# R7FA8M1AH register map
Vendor: Renesas; Series: RA8; File version: 1.2
CPU: CM85 r0p0, little endian, MPU, FPU, VTOR, 4 interrupt priority bits
Registers are 32-bit, read-write, reset 0x0 unless marked. A register's access mark holds for its fields unless they carry their own. Offsets are from the block's base; [hi:lo] are bit positions; {n}, {i} and the like mark numbered series; 'fields as' and 'values as' point back to an identical list.

## DSILINK (part 1 of 4)
Base 0x40346000
Same registers: DSILINK_NS 0x50346000
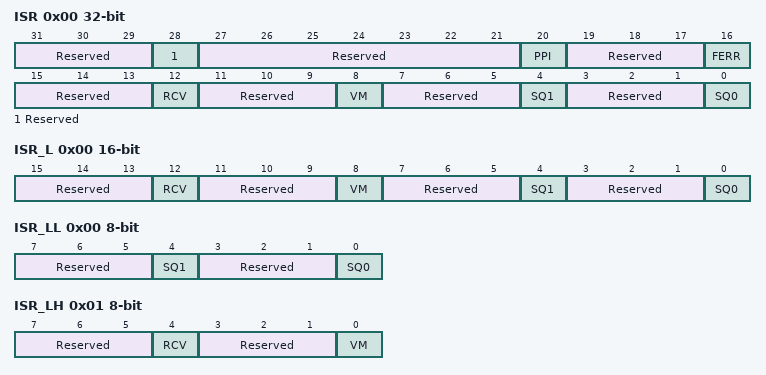
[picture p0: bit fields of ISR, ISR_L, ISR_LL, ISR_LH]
0x00 ISR ro — Interrupt Status Register
  [31:29] Reserved — These bits are read as 000.
  [28] Reserved — This bit is read as 0.
  [27:21] Reserved — These bits are read as 0000000.
  [20] PPI — PPI Interrupt Flag
    0=No interrupt detected; 1=PPI interrupt detected
  [19:17] Reserved — These bits are read as 000.
  [16] FERR — Fatal Error Interrupt Flag
    0=No interrupt detected; 1=Fatal Error interrupt detected
  [15:13] Reserved — These bits are read as 000.
  [12] RCV — Receive Interrupt Flag
    0=No interrupt detected; 1=Receive interrupt detected
  [11:9] Reserved — These bits are read as 000.
  [8] VM — Video Mode Interrupt Flag
    0=No interrupt detected; 1=Video Mode interrupt detected
  [7:5] Reserved — These bits are read as 000.
  [4] SQ1 — Sequence Channel-1 Interrupt Flag
    0=No interrupt detected; 1=Sequence Operation Channel-1 interrupt detected
  [3:1] Reserved — These bits are read as 000.
  [0] SQ0 — Sequence Channel-0 Interrupt Flag
    0=No interrupt detected; 1=Sequence Operation Channel-0 interrupt detected
0x00 ISR_L 16-bit ro (alternate view of ISR) — Interrupt Status Register
  [15:13] Reserved — These bits are read as 000.
  [12] RCV — Receive Interrupt Flag
    0=No interrupt detected; 1=Receive interrupt detected
  [11:9] Reserved — These bits are read as 000.
  [8] VM — Video Mode Interrupt Flag
    0=No interrupt detected; 1=Video Mode interrupt detected
  [7:5] Reserved — These bits are read as 000.
  [4] SQ1 — Sequence Channel-1 Interrupt Flag
    values as ISR.SQ1
  [3:1] Reserved — These bits are read as 000.
  [0] SQ0 — Sequence Channel-0 Interrupt Flag
    values as ISR.SQ0
0x00 ISR_LL 8-bit ro (alternate view of ISR) — Interrupt Status Register
  [7:5] Reserved — These bits are read as 000.
  [4] SQ1 — Sequence Channel-1 Interrupt Flag
    values as ISR.SQ1
  [3:1] Reserved — These bits are read as 000.
  [0] SQ0 — Sequence Channel-0 Interrupt Flag
    values as ISR.SQ0
0x01 ISR_LH 8-bit ro (alternate view of ISR) — Interrupt Status Register
  [7:5] Reserved — These bits are read as 000.
  [4] RCV — Receive Interrupt Flag
    0=No interrupt detected; 1=Receive interrupt detected
  [3:1] Reserved — These bits are read as 000.
  [0] VM — Video Mode Interrupt Flag
    0=No interrupt detected; 1=Video Mode interrupt detected
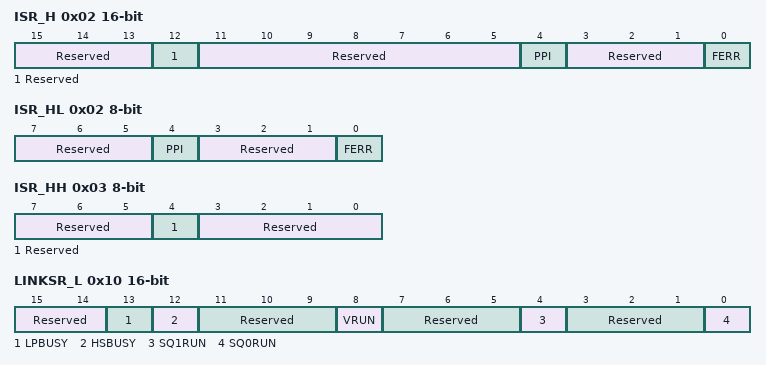
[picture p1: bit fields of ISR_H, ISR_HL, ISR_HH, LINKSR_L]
0x02 ISR_H 16-bit ro (alternate view of ISR) — Interrupt Status Register
  [15:13] Reserved — These bits are read as 000.
  [12] Reserved — This bit is read as 0.
  [11:5] Reserved — These bits are read as 0000000.
  [4] PPI — PPI Interrupt Flag
    0=No interrupt detected; 1=PPI interrupt detected
  [3:1] Reserved — These bits are read as 000.
  [0] FERR — Fatal Error Interrupt Flag
    0=No interrupt detected; 1=Fatal Error interrupt detected
0x02 ISR_HL 8-bit ro (alternate view of ISR) — Interrupt Status Register
  [7:5] Reserved — These bits are read as 000.
  [4] PPI — PPI Interrupt Flag
    0=No interrupt detected; 1=PPI interrupt detected
  [3:1] Reserved — These bits are read as 000.
  [0] FERR — Fatal Error Interrupt Flag
    0=No interrupt detected; 1=Fatal Error interrupt detected
0x03 ISR_HH 8-bit ro (alternate view of ISR) — Interrupt Status Register
  [7:5] Reserved — These bits are read as 000.
  [4] Reserved — This bit is read as 0.
  [3:0] Reserved — These bits are read as 0000.
0x10 LINKSR_L 16-bit ro (alternate view of LINKSR) — Link Status Register
  [15:14] Reserved — These bits are read as 00.
  [13] LPBUSY — LP Operation Busy Flag
    0=LP mode stopped; 1=LP mode in operation
  [12] HSBUSY — HS Operation Busy Flag
    0=HS mode stopped; 1=HS mode in operation
  [11:9] Reserved — These bits are read as 000.
  [8] VRUN — Video Mode Operation Running Flag
    0=Video mode stopped; 1=Video mode in operation
  [7:5] Reserved — These bits are read as 000.
  [4] SQ1RUN — Sequence Channel-1 Running Flag
    0=Sequence Operation Channel-1 stopped; 1=Sequence Operation Channel-1 in operation
  [3:1] Reserved — These bits are read as 000.
  [0] SQ0RUN — Sequence Channel-0 Running Flag
    0=Sequence Operation Channel-0 stopped; 1=Sequence Operation Channel-0 in operation
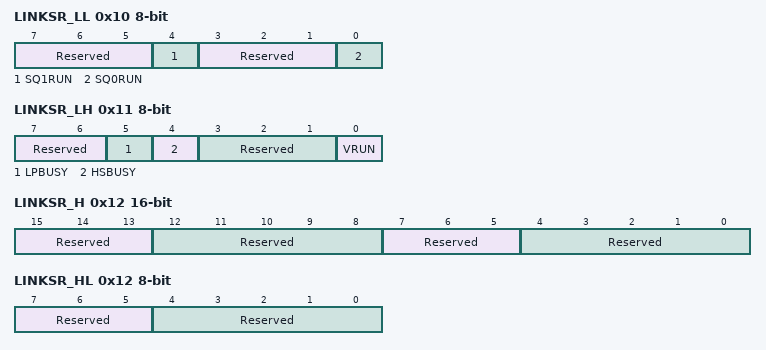
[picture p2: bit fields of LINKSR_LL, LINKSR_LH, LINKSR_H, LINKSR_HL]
0x10 LINKSR_LL 8-bit ro (alternate view of LINKSR) — Link Status Register
  [7:5] Reserved — These bits are read as 000.
  [4] SQ1RUN — Sequence Channel-1 Running Flag
    values as LINKSR_L.SQ1RUN
  [3:1] Reserved — These bits are read as 000.
  [0] SQ0RUN — Sequence Channel-0 Running Flag
    values as LINKSR_L.SQ0RUN
0x11 LINKSR_LH 8-bit ro (alternate view of LINKSR) — Link Status Register
  [7:6] Reserved — These bits are read as 00.
  [5] LPBUSY — LP Operation Busy Flag
    0=LP mode stopped; 1=LP mode in operation
  [4] HSBUSY — HS Operation Busy Flag
    0=HS mode stopped; 1=HS mode in operation
  [3:1] Reserved — These bits are read as 000.
  [0] VRUN — Video Mode Operation Running Flag
    0=Video mode stopped; 1=Video mode in operation
0x12 LINKSR_H 16-bit ro (alternate view of LINKSR) — Link Status Register
  [15:13] Reserved — These bits are read as 000.
  [12:8] Reserved — These bits are read as 00000.
  [7:5] Reserved — These bits are read as 000.
  [4:0] Reserved — These bits are read as 00000.
0x12 LINKSR_HL 8-bit ro (alternate view of LINKSR) — Link Status Register
  [7:5] Reserved — These bits are read as 000.
  [4:0] Reserved — These bits are read as 00000.
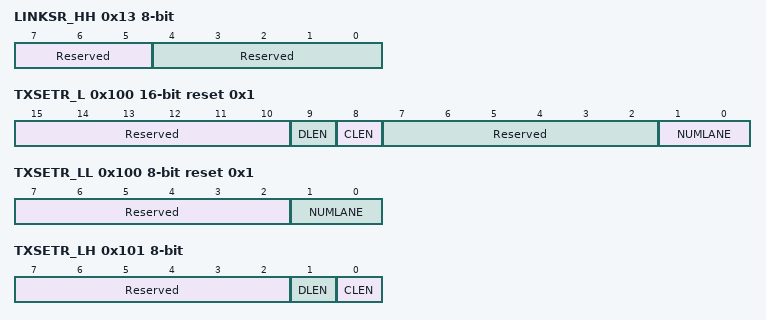
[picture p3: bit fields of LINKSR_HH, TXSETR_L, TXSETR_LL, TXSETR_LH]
0x13 LINKSR_HH 8-bit ro (alternate view of LINKSR) — Link Status Register
  fields as LINKSR_HL
0x100 TXSETR_L 16-bit reset 0x1 (alternate view of TXSETR) — Transmit Set Register
  [15:10] Reserved — These bits are read as 000000. The write value should be 000000.
  [9] DLEN — Data Lane Enable
    0=Disable; 1=Enable
  [8] CLEN — Clock Lane Enable
    0=Disable; 1=Enable
  [7:2] Reserved — These bits are read as 000000. The write value should be 000000.
  [1:0] NUMLANE — Number of Lane
    0=1 Lane (Use of Lane-0); 1=2 Lane (Use of Lane-0 and Lane-1)
0x100 TXSETR_LL 8-bit reset 0x1 (alternate view of TXSETR) — Transmit Set Register
  [7:2] Reserved — These bits are read as 000000. The write value should be 000000.
  [1:0] NUMLANE — Number of Lane
    values as TXSETR_L.NUMLANE
0x101 TXSETR_LH 8-bit (alternate view of TXSETR) — Transmit Set Register
  [7:2] Reserved — These bits are read as 000000. The write value should be 000000.
  [1] DLEN — Data Lane Enable
    0=Disable; 1=Enable
  [0] CLEN — Clock Lane Enable
    0=Disable; 1=Enable
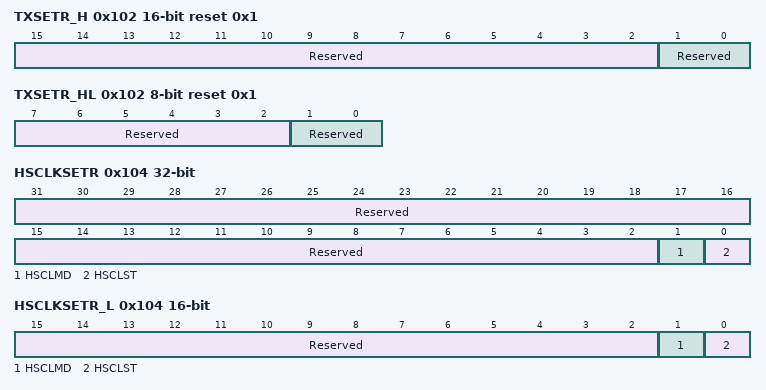
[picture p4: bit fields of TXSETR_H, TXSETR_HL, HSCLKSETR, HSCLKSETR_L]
0x102 TXSETR_H 16-bit ro reset 0x1 (alternate view of TXSETR) — Transmit Set Register
  [15:2] Reserved — These bits are read as 00000000000000.
  [1:0] Reserved — These bits are read as 01.
0x102 TXSETR_HL 8-bit ro reset 0x1 (alternate view of TXSETR) — Transmit Set Register
  [7:2] Reserved — These bits are read as 000000.
  [1:0] Reserved — These bits are read as 01.
0x104 HSCLKSETR — HS Clock Set Register
  [31:2] Reserved — These bits are read as 000000000000000000000000000000. The write value should be 000000000000000000000000000000.
  [1] HSCLMD — HS Clock Running Mode
    0=Non-continuous clock mode; 1=Continuous clock mode
  [0] HSCLST — HS Clock Start
    0=Stop HS transmission (keep LP state); 1=Start HS transmission
0x104 HSCLKSETR_L 16-bit (alternate view of HSCLKSETR) — HS Clock Set Register
  [15:2] Reserved — These bits are read as 00000000000000. The write value should be 00000000000000.
  [1] HSCLMD — HS Clock Running Mode
    0=Non-continuous clock mode; 1=Continuous clock mode
  [0] HSCLST — HS Clock Start
    values as HSCLKSETR.HSCLST
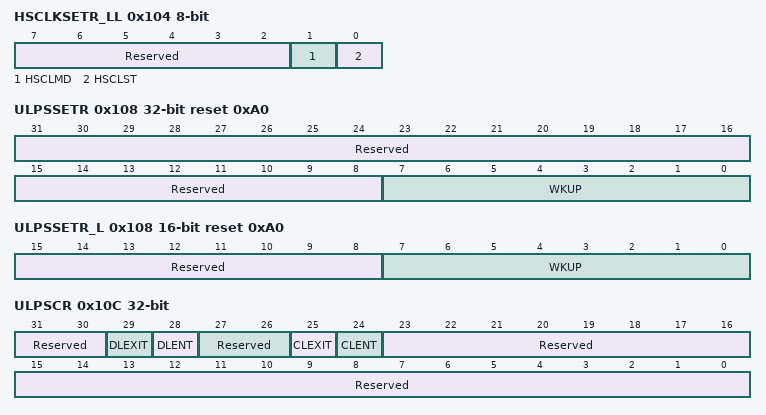
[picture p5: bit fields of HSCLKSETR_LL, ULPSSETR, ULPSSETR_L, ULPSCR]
0x104 HSCLKSETR_LL 8-bit (alternate view of HSCLKSETR) — HS Clock Set Register
  [7:2] Reserved — These bits are read as 000000. The write value should be 000000.
  [1] HSCLMD — HS Clock Running Mode
    0=Non-continuous clock mode; 1=Continuous clock mode
  [0] HSCLST — HS Clock Start
    values as HSCLKSETR.HSCLST
0x108 ULPSSETR reset 0xA0 — ULPS Set Register
  [31:8] Reserved — These bits are read as 000000000000000000000000. The write value should be 000000000000000000000000.
  [7:0] WKUP — ULPS Wakeup Period
0x108 ULPSSETR_L 16-bit reset 0xA0 (alternate view of ULPSSETR) — ULPS Set Register
  [15:8] Reserved — These bits are read as 00000000. The write value should be 00000000.
  [7:0] WKUP — ULPS Wakeup Period
0x108 ULPSSETR_LL 8-bit reset 0xA0 (alternate view of ULPSSETR) — ULPS Set Register
  [7:0] WKUP — ULPS Wakeup Period
0x10C ULPSCR wo — ULPS Control Register
  [31:30] Reserved — The write value should be 00.
  [29] DLEXIT — DL ULPS Exit
    0=No operation; 1=Data Lanes exit from ULPS
  [28] DLENT — DL ULPS Enter
    0=No operation; 1=Transition Data Lanes to ULPS
  [27:26] Reserved — The write value should be 00.
  [25] CLEXIT — CL ULPS Exit
    0=No operation; 1=Clock Lane exits from ULPS
  [24] CLENT — CL ULPS Enter
    0=No operation; 1=Transition Clock Lane to ULPS
  [23:0] Reserved — The write value should be 000000000000000000000000.
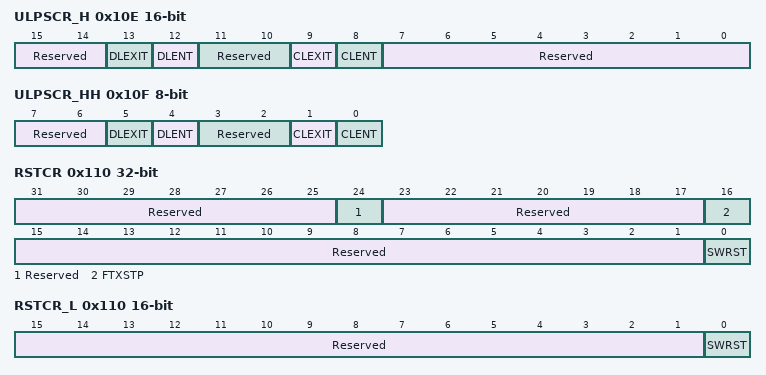
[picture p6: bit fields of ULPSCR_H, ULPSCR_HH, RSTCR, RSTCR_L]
0x10E ULPSCR_H 16-bit wo (alternate view of ULPSCR) — ULPS Control Register
  [15:14] Reserved — The write value should be 00.
  [13] DLEXIT — DL ULPS Exit
    0=No operation; 1=Data Lanes exit from ULPS
  [12] DLENT — DL ULPS Enter
    0=No operation; 1=Transition Data Lanes to ULPS
  [11:10] Reserved — The write value should be 00.
  [9] CLEXIT — CL ULPS Exit
    0=No operation; 1=Clock Lane exits from ULPS
  [8] CLENT — CL ULPS Enter
    0=No operation; 1=Transition Clock Lane to ULPS
  [7:0] Reserved — The write value should be 00000000.
0x10F ULPSCR_HH 8-bit wo (alternate view of ULPSCR) — ULPS Control Register
  [7:6] Reserved — The write value should be 00.
  [5] DLEXIT — DL ULPS Exit
    0=No operation; 1=Data Lanes exit from ULPS
  [4] DLENT — DL ULPS Enter
    0=No operation; 1=Transition Data Lanes to ULPS
  [3:2] Reserved — The write value should be 00.
  [1] CLEXIT — CL ULPS Exit
    0=No operation; 1=Clock Lane exits from ULPS
  [0] CLENT — CL ULPS Enter
    0=No operation; 1=Transition Clock Lane to ULPS
0x110 RSTCR — Reset Control Register
  [31:25] Reserved — These bits are read as 0000000. The write value should be 0000000.
  [24] Reserved — This bit is read as 0. The write value should be 0.
  [23:17] Reserved — These bits are read as 0000000. The write value should be 0000000.
  [16] FTXSTP — Force Tx Stop Mode
    0=Finish the Force Stop state; 1=Force Data Lanes into transmit mode and generate Stop state
  [15:1] Reserved — These bits are read as 000000000000000. The write value should be 000000000000000.
  [0] SWRST — Software Reset
    0=Complete the Software Reset; 1=Request a Software Reset
0x110 RSTCR_L 16-bit (alternate view of RSTCR) — Reset Control Register
  [15:1] Reserved — These bits are read as 000000000000000. The write value should be 000000000000000.
  [0] SWRST — Software Reset
    0=Complete the Software Reset; 1=Request a Software Reset
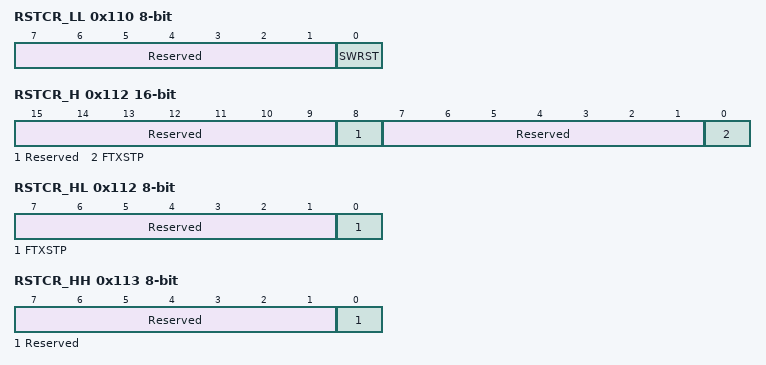
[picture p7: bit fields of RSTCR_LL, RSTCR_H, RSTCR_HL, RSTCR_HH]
0x110 RSTCR_LL 8-bit (alternate view of RSTCR) — Reset Control Register
  [7:1] Reserved — These bits are read as 0000000. The write value should be 0000000.
  [0] SWRST — Software Reset
    0=Complete the Software Reset; 1=Request a Software Reset
0x112 RSTCR_H 16-bit (alternate view of RSTCR) — Reset Control Register
  [15:9] Reserved — These bits are read as 0000000. The write value should be 0000000.
  [8] Reserved — This bit is read as 0. The write value should be 0.
  [7:1] Reserved — These bits are read as 0000000. The write value should be 0000000.
  [0] FTXSTP — Force Tx Stop Mode
    values as RSTCR.FTXSTP
0x112 RSTCR_HL 8-bit (alternate view of RSTCR) — Reset Control Register
  [7:1] Reserved — These bits are read as 0000000. The write value should be 0000000.
  [0] FTXSTP — Force Tx Stop Mode
    values as RSTCR.FTXSTP
0x113 RSTCR_HH 8-bit (alternate view of RSTCR) — Reset Control Register
  [7:1] Reserved — These bits are read as 0000000. The write value should be 0000000.
  [0] Reserved — This bit is read as 0. The write value should be 0.
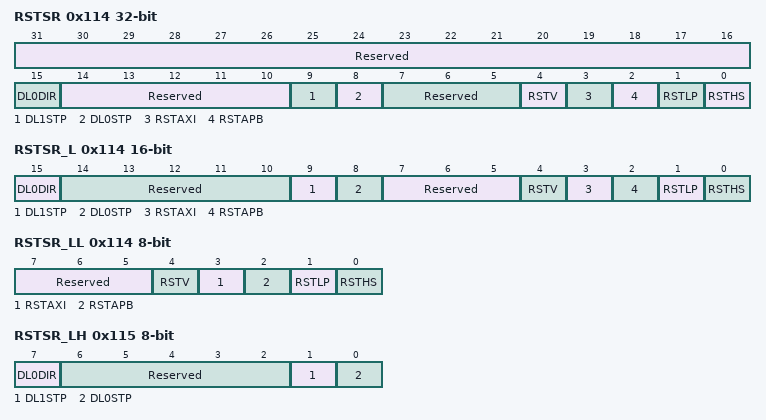
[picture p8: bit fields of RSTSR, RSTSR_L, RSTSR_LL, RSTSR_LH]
0x114 RSTSR ro — Reset Status Register
  [31:16] Reserved — These bits are read as 0000000000000000.
  [15] DL0DIR — Data Lane-0 Direction
    0=TX mode; 1=RX mode
  [14:10] Reserved — These bits are read as 00000.
  [9] DL1STP — Data Lane-1 Stop Status
    0=Not Stop state; 1=Stop state
  [8] DL0STP — Data Lane-0 Stop Status
    0=Not Stop state; 1=Stop state
  [7:5] Reserved — These bits are read as 000.
  [4] RSTV — Video Software Reset Status
    0=Not in software reset procedure; 1=Running software reset procedure for Video mode
  [3] RSTAXI — AXI Software Reset Status
    0=Not in software reset procedure; 1=Running software reset procedure for AXI bus
  [2] RSTAPB — APB Software Reset Status
    0=Not in software reset procedure; 1=Running software reset procedure for APB bus
  [1] RSTLP — LP Software Reset Status
    0=Not in software reset procedure; 1=Running software reset procedure for LP mode
  [0] RSTHS — HS Software Reset Status
    0=Not in software reset procedure; 1=Running software reset procedure for HS mode
0x114 RSTSR_L 16-bit ro (alternate view of RSTSR) — Reset Status Register
  [15] DL0DIR — Data Lane-0 Direction
    0=TX mode; 1=RX mode
  [14:10] Reserved — These bits are read as 00000.
  [9] DL1STP — Data Lane-1 Stop Status
    0=Not Stop state; 1=Stop state
  [8] DL0STP — Data Lane-0 Stop Status
    0=Not Stop state; 1=Stop state
  [7:5] Reserved — These bits are read as 000.
  [4] RSTV — Video Software Reset Status
    values as RSTSR.RSTV
  [3] RSTAXI — AXI Software Reset Status
    values as RSTSR.RSTAXI
  [2] RSTAPB — APB Software Reset Status
    values as RSTSR.RSTAPB
  [1] RSTLP — LP Software Reset Status
    values as RSTSR.RSTLP
  [0] RSTHS — HS Software Reset Status
    values as RSTSR.RSTHS
0x114 RSTSR_LL 8-bit ro (alternate view of RSTSR) — Reset Status Register
  [7:5] Reserved — These bits are read as 000.
  [4] RSTV — Video Software Reset Status
    values as RSTSR.RSTV
  [3] RSTAXI — AXI Software Reset Status
    values as RSTSR.RSTAXI
  [2] RSTAPB — APB Software Reset Status
    values as RSTSR.RSTAPB
  [1] RSTLP — LP Software Reset Status
    values as RSTSR.RSTLP
  [0] RSTHS — HS Software Reset Status
    values as RSTSR.RSTHS
0x115 RSTSR_LH 8-bit ro (alternate view of RSTSR) — Reset Status Register
  [7] DL0DIR — Data Lane-0 Direction
    0=TX mode; 1=RX mode
  [6:2] Reserved — These bits are read as 00000.
  [1] DL1STP — Data Lane-1 Stop Status
    0=Not Stop state; 1=Stop state
  [0] DL0STP — Data Lane-0 Stop Status
    0=Not Stop state; 1=Stop state
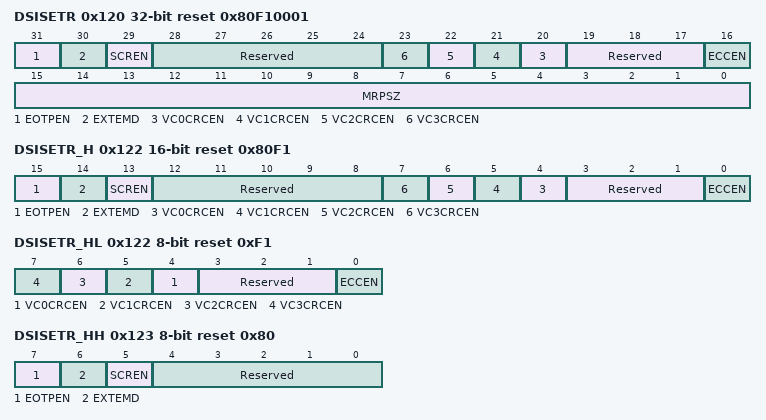
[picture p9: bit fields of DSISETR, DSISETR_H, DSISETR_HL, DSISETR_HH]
0x120 DSISETR reset 0x80F10001 — DSI Set Register
  [31] EOTPEN — HS Transfer EoTp Enable
    0=Disable; 1=Enable
  [30] EXTEMD — External Tearing Effect Detection Sense Select
    0=Rising edge; 1=Falling edge
  [29] SCREN — Data Scramble Enable
    0=Disable; 1=Enable
  [28:24] Reserved — These bits are read as 00000. The write value should be 00000.
  [n+20] VC{n}CRCEN (n=0..3) — VC-{n} CRC Check Enable
    0=Disable; 1=Enable
  [19:17] Reserved — These bits are read as 000. The write value should be 000.
  [16] ECCEN — ECC Check Enable
    0=Disable; 1=Enable
  [15:0] MRPSZ — Maximum Return Packet Size
0x120 DSISETR_L 16-bit reset 0x1 (alternate view of DSISETR) — DSI Set Register
  [15:0] MRPSZ — Maximum Return Packet Size
0x120 DSISETR_LL 8-bit reset 0x1 (alternate view of DSISETR) — DSI Set Register
  [7:0] MRPSZ — Maximum Return Packet Size
0x121 DSISETR_LH 8-bit (alternate view of DSISETR) — DSI Set Register
  [7:0] MRPSZ — Maximum Return Packet Size
0x122 DSISETR_H 16-bit reset 0x80F1 (alternate view of DSISETR) — DSI Set Register
  [15] EOTPEN — HS Transfer EoTp Enable
    0=Disable; 1=Enable
  [14] EXTEMD — External Tearing Effect Detection Sense Select
    0=Rising edge; 1=Falling edge
  [13] SCREN — Data Scramble Enable
    0=Disable; 1=Enable
  [12:8] Reserved — These bits are read as 00000. The write value should be 00000.
  [n+4] VC{n}CRCEN (n=0..3) — VC-{n} CRC Check Enable
    0=Disable; 1=Enable
  [3:1] Reserved — These bits are read as 000. The write value should be 000.
  [0] ECCEN — ECC Check Enable
    0=Disable; 1=Enable
0x122 DSISETR_HL 8-bit reset 0xF1 (alternate view of DSISETR) — DSI Set Register
  [n+4] VC{n}CRCEN (n=0..3) — VC-{n} CRC Check Enable
    0=Disable; 1=Enable
  [3:1] Reserved — These bits are read as 000. The write value should be 000.
  [0] ECCEN — ECC Check Enable
    0=Disable; 1=Enable
0x123 DSISETR_HH 8-bit reset 0x80 (alternate view of DSISETR) — DSI Set Register
  [7] EOTPEN — HS Transfer EoTp Enable
    0=Disable; 1=Enable
  [6] EXTEMD — External Tearing Effect Detection Sense Select
    0=Rising edge; 1=Falling edge
  [5] SCREN — Data Scramble Enable
    0=Disable; 1=Enable
  [4:0] Reserved — These bits are read as 00000. The write value should be 00000.
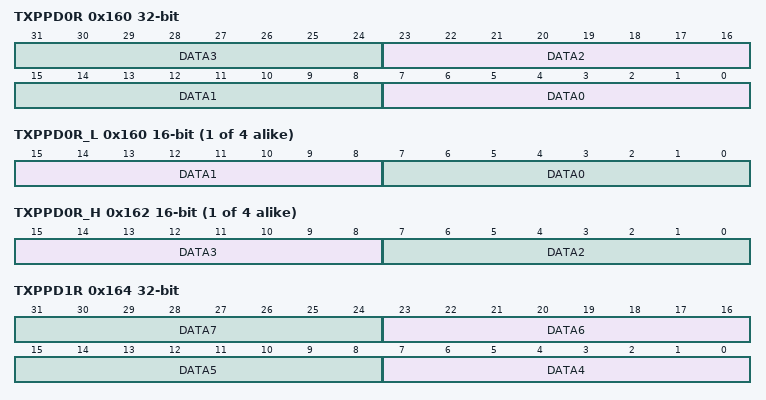
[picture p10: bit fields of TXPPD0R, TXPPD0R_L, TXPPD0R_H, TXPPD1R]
0x160 TXPPD0R — Transmit Packet Payload Data 0 Register
  [8n+7:8n] DATA{n} (n=0..3) — Payload Data {n}
{0x160+4i} TXPPD{i}R_L 16-bit (alternate view of TXPPD{i}R) (i=0..3) — Transmit Packet Payload Data {i} Register
  [15:8] DATA{4i+1} — Payload Data {4i+1}
  [7:0] DATA{4i} — Payload Data {4i}
{0x160+4i} TXPPD{i}R_LL 8-bit (alternate view of TXPPD{i}R) (i=0..3) — Transmit Packet Payload Data {i} Register
  [7:0] DATA{4i} — Payload Data {4i}
{0x161+4i} TXPPD{i}R_LH 8-bit (alternate view of TXPPD{i}R) (i=0..3) — Transmit Packet Payload Data {i} Register
  [7:0] DATA{4i+1} — Payload Data {4i+1}
{0x162+4i} TXPPD{i}R_H 16-bit (alternate view of TXPPD{i}R) (i=0..3) — Transmit Packet Payload Data {i} Register
  [15:8] DATA{4i+3} — Payload Data {4i+3}
  [7:0] DATA{4i+2} — Payload Data {4i+2}
{0x162+4i} TXPPD{i}R_HL 8-bit (alternate view of TXPPD{i}R) (i=0..3) — Transmit Packet Payload Data {i} Register
  [7:0] DATA{4i+2} — Payload Data {4i+2}
{0x163+4i} TXPPD{i}R_HH 8-bit (alternate view of TXPPD{i}R) (i=0..3) — Transmit Packet Payload Data {i} Register
  [7:0] DATA{4i+3} — Payload Data {4i+3}
0x164 TXPPD1R — Transmit Packet Payload Data 1 Register
  [8n-25:8n-32] DATA{n} (n=4..7) — Payload Data {n}
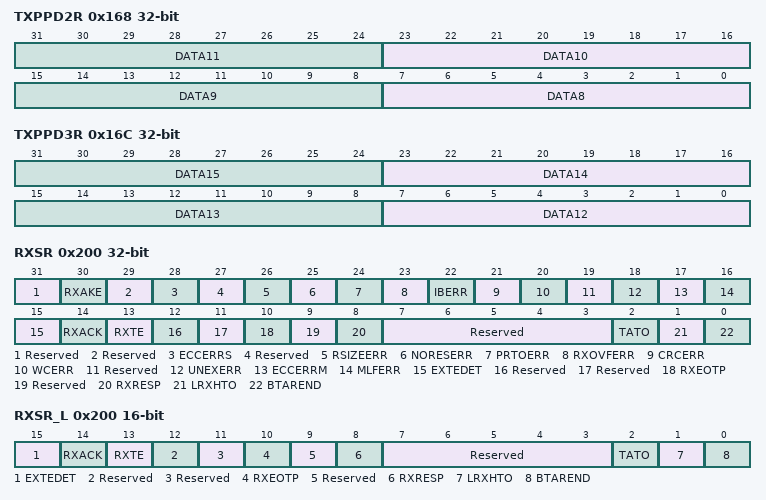
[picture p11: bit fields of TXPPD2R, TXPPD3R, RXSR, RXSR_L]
0x168 TXPPD2R — Transmit Packet Payload Data 2 Register
  [8n-57:8n-64] DATA{n} (n=8..11) — Payload Data {n}
0x16C TXPPD3R — Transmit Packet Payload Data 3 Register
  [8n-89:8n-96] DATA{n} (n=12..15) — Payload Data {n}
0x200 RXSR ro — Receive Status Register
  [31] Reserved — This bit is read as 0.
  [30] RXAKE — Acknowledge and Error Report Receive Interrupt Flag
    0=No received; 1=An Acknowledge and Error Report packet received
  [29] Reserved — This bit is read as 0.
  [28] ECCERRS — Single Bit ECC Error Interrupt Flag
    0=No error detected; 1=A single-bit ECC error detected
  [27] Reserved — This bit is read as 0.
  [26] RSIZEERR — Return Packet Size Error Interrupt Flag
    0=No error detected; 1=Oversize error in a received long packet detected
  [25] NORESERR — No Response Error Interrupt Flag
    0=No error occurred; 1=No triggers or packets returned during BTA period
  [24] PRTOERR — Peripheral Response Timeout Error Interrupt Flag
    0=No error occurred; 1=Peripheral response timeout occurred
  [23] RXOVFERR — Receive Buffer Overflow Error Interrupt Flag
    0=No error detected; 1=A buffer overflow error detected on receiving long packets
  [22] IBERR — Internal Bus Error Interrupt Flag
    0=No error detected; 1=Internal AXI bus write failed
  [21] CRCERR — CRC Error Interrupt Flag
    0=No error detected; 1=CRC error detected
  [20] WCERR — Word Count Error Interrupt Flag
    0=No error detected; 1=The length of the received packet is shorter than the WC indicated in the packet header
  [19] Reserved — This bit is read as 0.
  [18] UNEXERR — Unexpected Packet Error Interrupt Flag
    0=No error; 1=Unexpected packet received
  [17] ECCERRM — Multi Bit ECC Error Interrupt Flag
    0=No error detected; 1=A multi-bit ECC error detected
  [16] MLFERR — Malform Error Interrupt Flag
    0=No error received; 1=A packet of less than 4 bytes received
  [15] EXTEDET — External Tearing Effect Detect Interrupt Flag
    0=Not detected; 1=External Tearing Effect detected
  [14] RXACK — ACK Trigger Receive Interrupt Flag
    0=No trigger received; 1=ACK trigger received
  [13] RXTE — Tearing Effect Trigger Receive Interrupt Flag
    0=No trigger received; 1=Tearing Effect Trigger received
  [12] Reserved — This bit is read as 0.
  [11] Reserved — This bit is read as 0.
  [10] RXEOTP — EoTp Receive Interrupt Flag
    0=No received; 1=EoTp received
  [9] Reserved — This bit is read as 0.
  [8] RXRESP — Response Packet Receive Interrupt Flag
    0=No response received; 1=Response packet received
  [7:3] Reserved — These bits are read as 00000.
  [2] TATO — Turnaround Acknowledge Timeout Interrupt Flag
    0=Not detected; 1=Turnaround Acknowledge Timeout (TA_TO) detected
  [1] LRXHTO — LP-RX Host Processor Timeout Interrupt Flag
    0=Not detected; 1=LP-RX Host Processor Timeout (LRX-H_TO) detected
  [0] BTAREND — BTA Request End Interrupt Flag
    0=Not detected; 1=BTA Completion detected
0x200 RXSR_L 16-bit ro (alternate view of RXSR) — Receive Status Register
  [15] EXTEDET — External Tearing Effect Detect Interrupt Flag
    0=Not detected; 1=External Tearing Effect detected
  [14] RXACK — ACK Trigger Receive Interrupt Flag
    0=No trigger received; 1=ACK trigger received
  [13] RXTE — Tearing Effect Trigger Receive Interrupt Flag
    0=No trigger received; 1=Tearing Effect Trigger received
  [12] Reserved — This bit is read as 0.
  [11] Reserved — This bit is read as 0.
  [10] RXEOTP — EoTp Receive Interrupt Flag
    0=No received; 1=EoTp received
  [9] Reserved — This bit is read as 0.
  [8] RXRESP — Response Packet Receive Interrupt Flag
    0=No response received; 1=Response packet received
  [7:3] Reserved — These bits are read as 00000.
  [2] TATO — Turnaround Acknowledge Timeout Interrupt Flag
    values as RXSR.TATO
  [1] LRXHTO — LP-RX Host Processor Timeout Interrupt Flag
    values as RXSR.LRXHTO
  [0] BTAREND — BTA Request End Interrupt Flag
    0=Not detected; 1=BTA Completion detected
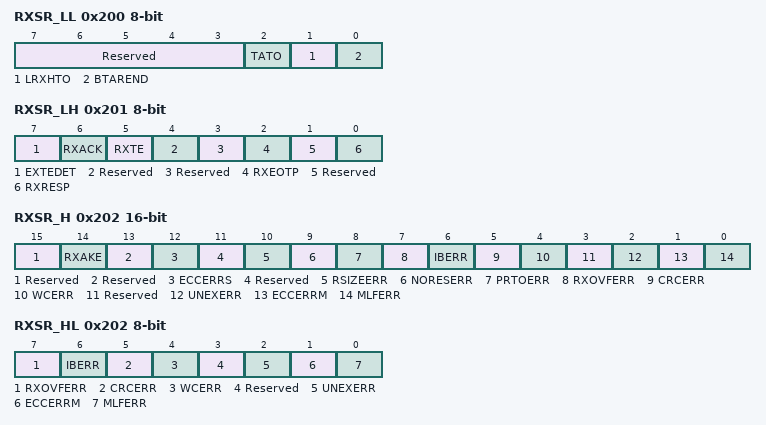
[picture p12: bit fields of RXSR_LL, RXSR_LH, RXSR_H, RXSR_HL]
0x200 RXSR_LL 8-bit ro (alternate view of RXSR) — Receive Status Register
  [7:3] Reserved — These bits are read as 00000.
  [2] TATO — Turnaround Acknowledge Timeout Interrupt Flag
    values as RXSR.TATO
  [1] LRXHTO — LP-RX Host Processor Timeout Interrupt Flag
    values as RXSR.LRXHTO
  [0] BTAREND — BTA Request End Interrupt Flag
    0=Not detected; 1=BTA Completion detected
0x201 RXSR_LH 8-bit ro (alternate view of RXSR) — Receive Status Register
  [7] EXTEDET — External Tearing Effect Detect Interrupt Flag
    0=Not detected; 1=External Tearing Effect detected
  [6] RXACK — ACK Trigger Receive Interrupt Flag
    0=No trigger received; 1=ACK trigger received
  [5] RXTE — Tearing Effect Trigger Receive Interrupt Flag
    0=No trigger received; 1=Tearing Effect Trigger received
  [4] Reserved — This bit is read as 0.
  [3] Reserved — This bit is read as 0.
  [2] RXEOTP — EoTp Receive Interrupt Flag
    0=No received; 1=EoTp received
  [1] Reserved — This bit is read as 0.
  [0] RXRESP — Response Packet Receive Interrupt Flag
    0=No response received; 1=Response packet received
0x202 RXSR_H 16-bit ro (alternate view of RXSR) — Receive Status Register
  [15] Reserved — This bit is read as 0.
  [14] RXAKE — Acknowledge and Error Report Receive Interrupt Flag
    values as RXSR.RXAKE
  [13] Reserved — This bit is read as 0.
  [12] ECCERRS — Single Bit ECC Error Interrupt Flag
    0=No error detected; 1=A single-bit ECC error detected
  [11] Reserved — This bit is read as 0.
  [10] RSIZEERR — Return Packet Size Error Interrupt Flag
    values as RXSR.RSIZEERR
  [9] NORESERR — No Response Error Interrupt Flag
    values as RXSR.NORESERR
  [8] PRTOERR — Peripheral Response Timeout Error Interrupt Flag
    0=No error occurred; 1=Peripheral response timeout occurred
  [7] RXOVFERR — Receive Buffer Overflow Error Interrupt Flag
    values as RXSR.RXOVFERR
  [6] IBERR — Internal Bus Error Interrupt Flag
    0=No error detected; 1=Internal AXI bus write failed
  [5] CRCERR — CRC Error Interrupt Flag
    0=No error detected; 1=CRC error detected
  [4] WCERR — Word Count Error Interrupt Flag
    values as RXSR.WCERR
  [3] Reserved — This bit is read as 0.
  [2] UNEXERR — Unexpected Packet Error Interrupt Flag
    0=No error; 1=Unexpected packet received
  [1] ECCERRM — Multi Bit ECC Error Interrupt Flag
    0=No error detected; 1=A multi-bit ECC error detected
  [0] MLFERR — Malform Error Interrupt Flag
    values as RXSR.MLFERR
0x202 RXSR_HL 8-bit ro (alternate view of RXSR) — Receive Status Register
  [7] RXOVFERR — Receive Buffer Overflow Error Interrupt Flag
    values as RXSR.RXOVFERR
  [6] IBERR — Internal Bus Error Interrupt Flag
    0=No error detected; 1=Internal AXI bus write failed
  [5] CRCERR — CRC Error Interrupt Flag
    0=No error detected; 1=CRC error detected
  [4] WCERR — Word Count Error Interrupt Flag
    values as RXSR.WCERR
  [3] Reserved — This bit is read as 0.
  [2] UNEXERR — Unexpected Packet Error Interrupt Flag
    0=No error; 1=Unexpected packet received
  [1] ECCERRM — Multi Bit ECC Error Interrupt Flag
    0=No error detected; 1=A multi-bit ECC error detected
  [0] MLFERR — Malform Error Interrupt Flag
    values as RXSR.MLFERR
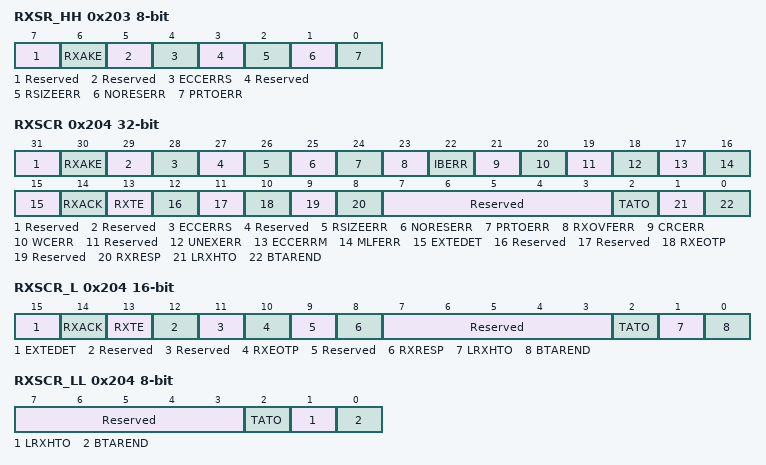
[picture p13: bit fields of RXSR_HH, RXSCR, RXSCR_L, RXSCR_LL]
0x203 RXSR_HH 8-bit ro (alternate view of RXSR) — Receive Status Register
  [7] Reserved — This bit is read as 0.
  [6] RXAKE — Acknowledge and Error Report Receive Interrupt Flag
    values as RXSR.RXAKE
  [5] Reserved — This bit is read as 0.
  [4] ECCERRS — Single Bit ECC Error Interrupt Flag
    0=No error detected; 1=A single-bit ECC error detected
  [3] Reserved — This bit is read as 0.
  [2] RSIZEERR — Return Packet Size Error Interrupt Flag
    values as RXSR.RSIZEERR
  [1] NORESERR — No Response Error Interrupt Flag
    values as RXSR.NORESERR
  [0] PRTOERR — Peripheral Response Timeout Error Interrupt Flag
    0=No error occurred; 1=Peripheral response timeout occurred
0x204 RXSCR — Receive Status Clear Register
  [31] Reserved — This bit is read as 0. The write value should be 0.
  [30] RXAKE write-1-clears read-modifies — Acknowledge and Error Report Receive Interrupt Flag Clear
    0=No operation; 1=Clear the RXSR.RXAKE flag
  [29] Reserved — This bit is read as 0. The write value should be 0.
  [28] ECCERRS write-1-clears read-modifies — Single Bit ECC Error Interrupt Flag Clear
    0=No operation; 1=Clear the RXSR.ECCERRS flag
  [27] Reserved — This bit is read as 0. The write value should be 0.
  [26] RSIZEERR write-1-clears read-modifies — Return Packet Size Error Interrupt Flag Clear
    0=No operation; 1=Clear the RXSR.RSIZEERR flag
  [25] NORESERR write-1-clears read-modifies — No Response Error Interrupt Flag Clear
    0=No operation; 1=Clear the RXSR.NORESERR flag
  [24] PRTOERR write-1-clears read-modifies — Peripheral Response Timeout Error Interrupt Flag Clear
    0=No operation; 1=Clear the RXSR.PRTOERR flag
  [23] RXOVFERR write-1-clears read-modifies — Receive Buffer Overflow Error Interrupt Flag Clear
    0=No operation; 1=Clear the RXSR.RXOVFERR flag
  [22] IBERR write-1-clears read-modifies — Internal Bus Error Interrupt Flag Clear
    0=No operation; 1=Clear the RXSR.IBERR flag
  [21] CRCERR write-1-clears read-modifies — CRC Error Interrupt Flag Clear
    0=No operation; 1=Clear the RXSR.CRCERR flag
  [20] WCERR write-1-clears read-modifies — Word Count Error Interrupt Flag Clear
    0=No operation; 1=Clear the RXSR.WCERR flag
  [19] Reserved — This bit is read as 0. The write value should be 0.
  [18] UNEXERR write-1-clears read-modifies — Unexpected Packet Error Interrupt Flag Clear
    0=No operation; 1=Clear the RXSR.UNEXERR flag
  [17] ECCERRM write-1-clears read-modifies — Multi Bit ECC Error Interrupt Flag Clear
    0=No operation; 1=Clear the RXSR.ECCERRM flag
  [16] MLFERR write-1-clears read-modifies — Malform Error Interrupt Flag Clear
    0=No operation; 1=Clear the RXSR.MLFERR flag
  [15] EXTEDET write-1-clears read-modifies — External Tearing Effect Detect Interrupt Flag Clear
    0=No operation; 1=Clear the RXSR.EXTEDET flag
  [14] RXACK write-1-clears read-modifies — ACK Trigger Receive Interrupt Flag Clear
    0=No operation; 1=Clear the RXSR.RXACK flag
  [13] RXTE write-1-clears read-modifies — Tearing Effect Trigger Receive Interrupt Flag Clear
    0=No operation; 1=Clear the RXSR.RXTE flag
  [12] Reserved — This bit is read as 0. The write value should be 0.
  [11] Reserved — This bit is read as 0. The write value should be 0.
  [10] RXEOTP write-1-clears read-modifies — EoTp Receive Interrupt Flag Clear
    0=No operation; 1=Clear the RXSR.RXEOTP flag
  [9] Reserved — This bit is read as 0. The write value should be 0.
  [8] RXRESP write-1-clears read-modifies — Response Packet Receive Interrupt Flag Clear
    0=No operation; 1=Clear the RXSR.RXRESP flag
  [7:3] Reserved — These bits are read as 00000. The write value should be 00000.
  [2] TATO write-1-clears read-modifies — Turnaround Acknowledge Timeout Interrupt Flag Clear
    0=No operation; 1=Clear the RXSR.TATO flag
  [1] LRXHTO write-1-clears read-modifies — LP-RX Host Processor Timeout Interrupt Flag Clear
    0=No operation; 1=Clear the RXSR.LRXHTO flag
  [0] BTAREND write-1-clears read-modifies — BTA Request End Interrupt Flag Clear
    0=No operation; 1=Clear the RXSR.BTAREND flag
0x204 RXSCR_L 16-bit (alternate view of RXSCR) — Receive Status Clear Register
  [15] EXTEDET write-1-clears read-modifies — External Tearing Effect Detect Interrupt Flag Clear
    0=No operation; 1=Clear the RXSR.EXTEDET flag
  [14] RXACK write-1-clears read-modifies — ACK Trigger Receive Interrupt Flag Clear
    0=No operation; 1=Clear the RXSR.RXACK flag
  [13] RXTE write-1-clears read-modifies — Tearing Effect Trigger Receive Interrupt Flag Clear
    0=No operation; 1=Clear the RXSR.RXTE flag
  [12] Reserved — This bit is read as 0. The write value should be 0.
  [11] Reserved — This bit is read as 0. The write value should be 0.
  [10] RXEOTP write-1-clears read-modifies — EoTp Receive Interrupt Flag Clear
    0=No operation; 1=Clear the RXSR.RXEOTP flag
  [9] Reserved — This bit is read as 0. The write value should be 0.
  [8] RXRESP write-1-clears read-modifies — Response Packet Receive Interrupt Flag Clear
    0=No operation; 1=Clear the RXSR.RXRESP flag
  [7:3] Reserved — These bits are read as 00000. The write value should be 00000.
  [2] TATO write-1-clears read-modifies — Turnaround Acknowledge Timeout Interrupt Flag Clear
    0=No operation; 1=Clear the RXSR.TATO flag
  [1] LRXHTO write-1-clears read-modifies — LP-RX Host Processor Timeout Interrupt Flag Clear
    0=No operation; 1=Clear the RXSR.LRXHTO flag
  [0] BTAREND write-1-clears read-modifies — BTA Request End Interrupt Flag Clear
    0=No operation; 1=Clear the RXSR.BTAREND flag
0x204 RXSCR_LL 8-bit (alternate view of RXSCR) — Receive Status Clear Register
  [7:3] Reserved — These bits are read as 00000. The write value should be 00000.
  [2] TATO write-1-clears read-modifies — Turnaround Acknowledge Timeout Interrupt Flag Clear
    0=No operation; 1=Clear the RXSR.TATO flag
  [1] LRXHTO write-1-clears read-modifies — LP-RX Host Processor Timeout Interrupt Flag Clear
    0=No operation; 1=Clear the RXSR.LRXHTO flag
  [0] BTAREND write-1-clears read-modifies — BTA Request End Interrupt Flag Clear
    0=No operation; 1=Clear the RXSR.BTAREND flag
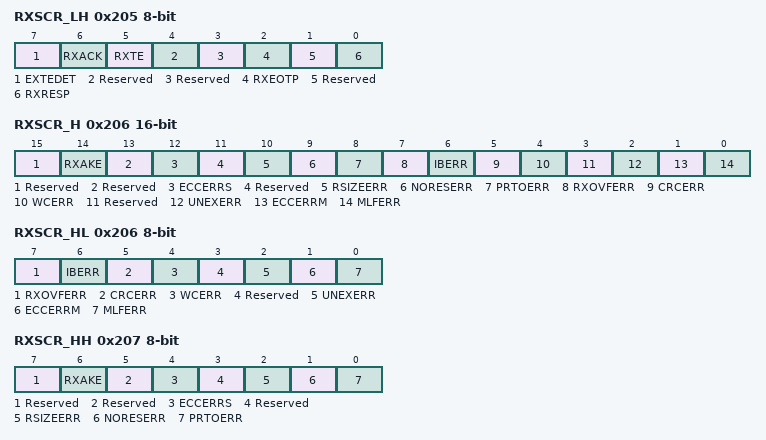
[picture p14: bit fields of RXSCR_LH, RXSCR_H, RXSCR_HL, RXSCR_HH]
0x205 RXSCR_LH 8-bit (alternate view of RXSCR) — Receive Status Clear Register
  [7] EXTEDET write-1-clears read-modifies — External Tearing Effect Detect Interrupt Flag Clear
    0=No operation; 1=Clear the RXSR.EXTEDET flag
  [6] RXACK write-1-clears read-modifies — ACK Trigger Receive Interrupt Flag Clear
    0=No operation; 1=Clear the RXSR.RXACK flag
  [5] RXTE write-1-clears read-modifies — Tearing Effect Trigger Receive Interrupt Flag Clear
    0=No operation; 1=Clear the RXSR.RXTE flag
  [4] Reserved — This bit is read as 0. The write value should be 0.
  [3] Reserved — This bit is read as 0. The write value should be 0.
  [2] RXEOTP write-1-clears read-modifies — EoTp Receive Interrupt Flag Clear
    0=No operation; 1=Clear the RXSR.RXEOTP flag
  [1] Reserved — This bit is read as 0. The write value should be 0.
  [0] RXRESP write-1-clears read-modifies — Response Packet Receive Interrupt Flag Clear
    0=No operation; 1=Clear the RXSR.RXRESP flag
0x206 RXSCR_H 16-bit (alternate view of RXSCR) — Receive Status Clear Register
  [15] Reserved — This bit is read as 0. The write value should be 0.
  [14] RXAKE write-1-clears read-modifies — Acknowledge and Error Report Receive Interrupt Flag Clear
    0=No operation; 1=Clear the RXSR.RXAKE flag
  [13] Reserved — This bit is read as 0. The write value should be 0.
  [12] ECCERRS write-1-clears read-modifies — Single Bit ECC Error Interrupt Flag Clear
    0=No operation; 1=Clear the RXSR.ECCERRS flag
  [11] Reserved — This bit is read as 0. The write value should be 0.
  [10] RSIZEERR write-1-clears read-modifies — Return Packet Size Error Interrupt Flag Clear
    0=No operation; 1=Clear the RXSR.RSIZEERR flag
  [9] NORESERR write-1-clears read-modifies — No Response Error Interrupt Flag Clear
    0=No operation; 1=Clear the RXSR.NORESERR flag
  [8] PRTOERR write-1-clears read-modifies — Peripheral Response Timeout Error Interrupt Flag Clear
    0=No operation; 1=Clear the RXSR.PRTOERR flag
  [7] RXOVFERR write-1-clears read-modifies — Receive Buffer Overflow Error Interrupt Flag Clear
    0=No operation; 1=Clear the RXSR.RXOVFERR flag
  [6] IBERR write-1-clears read-modifies — Internal Bus Error Interrupt Flag Clear
    0=No operation; 1=Clear the RXSR.IBERR flag
  [5] CRCERR write-1-clears read-modifies — CRC Error Interrupt Flag Clear
    0=No operation; 1=Clear the RXSR.CRCERR flag
  [4] WCERR write-1-clears read-modifies — Word Count Error Interrupt Flag Clear
    0=No operation; 1=Clear the RXSR.WCERR flag
  [3] Reserved — This bit is read as 0. The write value should be 0.
  [2] UNEXERR write-1-clears read-modifies — Unexpected Packet Error Interrupt Flag Clear
    0=No operation; 1=Clear the RXSR.UNEXERR flag
  [1] ECCERRM write-1-clears read-modifies — Multi Bit ECC Error Interrupt Flag Clear
    0=No operation; 1=Clear the RXSR.ECCERRM flag
  [0] MLFERR write-1-clears read-modifies — Malform Error Interrupt Flag Clear
    0=No operation; 1=Clear the RXSR.MLFERR flag
0x206 RXSCR_HL 8-bit (alternate view of RXSCR) — Receive Status Clear Register
  [7] RXOVFERR write-1-clears read-modifies — Receive Buffer Overflow Error Interrupt Flag Clear
    0=No operation; 1=Clear the RXSR.RXOVFERR flag
  [6] IBERR write-1-clears read-modifies — Internal Bus Error Interrupt Flag Clear
    0=No operation; 1=Clear the RXSR.IBERR flag
  [5] CRCERR write-1-clears read-modifies — CRC Error Interrupt Flag Clear
    0=No operation; 1=Clear the RXSR.CRCERR flag
  [4] WCERR write-1-clears read-modifies — Word Count Error Interrupt Flag Clear
    0=No operation; 1=Clear the RXSR.WCERR flag
  [3] Reserved — This bit is read as 0. The write value should be 0.
  [2] UNEXERR write-1-clears read-modifies — Unexpected Packet Error Interrupt Flag Clear
    0=No operation; 1=Clear the RXSR.UNEXERR flag
  [1] ECCERRM write-1-clears read-modifies — Multi Bit ECC Error Interrupt Flag Clear
    0=No operation; 1=Clear the RXSR.ECCERRM flag
  [0] MLFERR write-1-clears read-modifies — Malform Error Interrupt Flag Clear
    0=No operation; 1=Clear the RXSR.MLFERR flag
0x207 RXSCR_HH 8-bit (alternate view of RXSCR) — Receive Status Clear Register
  [7] Reserved — This bit is read as 0. The write value should be 0.
  [6] RXAKE write-1-clears read-modifies — Acknowledge and Error Report Receive Interrupt Flag Clear
    0=No operation; 1=Clear the RXSR.RXAKE flag
  [5] Reserved — This bit is read as 0. The write value should be 0.
  [4] ECCERRS write-1-clears read-modifies — Single Bit ECC Error Interrupt Flag Clear
    0=No operation; 1=Clear the RXSR.ECCERRS flag
  [3] Reserved — This bit is read as 0. The write value should be 0.
  [2] RSIZEERR write-1-clears read-modifies — Return Packet Size Error Interrupt Flag Clear
    0=No operation; 1=Clear the RXSR.RSIZEERR flag
  [1] NORESERR write-1-clears read-modifies — No Response Error Interrupt Flag Clear
    0=No operation; 1=Clear the RXSR.NORESERR flag
  [0] PRTOERR write-1-clears read-modifies — Peripheral Response Timeout Error Interrupt Flag Clear
    0=No operation; 1=Clear the RXSR.PRTOERR flag
